# Flash_5 register map
Vendor: Texas Instruments
Peripheral module from a debugger description file (folder msp430).
Registers are 16-bit, read-write, reset 0x0 unless marked. A register's access mark holds for its fields unless they carry their own. Offsets are as the file gives them; lines under a group give offsets from that group; [hi:lo] are bit positions; {n}, {i} and the like mark numbered series; 'fields as' and 'values as' point back to an identical list; <NAME> marks a mode.

## Flash
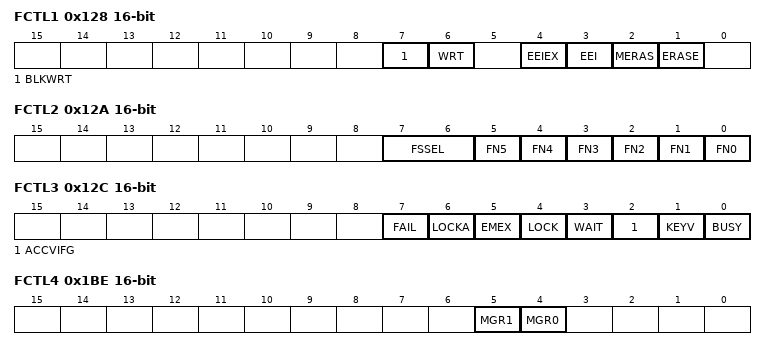
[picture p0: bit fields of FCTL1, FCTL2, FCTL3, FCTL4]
0x128 FCTL1 — FLASH Control 1
  [7] BLKWRT — Enable bit for Flash segment write
  [6] WRT — Enable bit for Flash write
  [4] EEIEX — Enable Emergency Interrupt Exit
  [3] EEI — Enable Erase Interrupts
  [2] MERAS — Enable bit for Flash mass erase
  [1] ERASE — Enable bit for Flash segment erase
0x12A FCTL2 — FLASH Control 2
  [7:6] FSSEL — Flash clock select 0 */ /* to distinguish from USART SSELx
    0=Flash clock select: 0 - ACLK; 1=Flash clock select: 1 - MCLK; 2=Flash clock select: 2 - SMCLK; 3=Flash clock select: 3 - SMCLK
  [n] FN{n} (n=2..5)
  [1] FN1 — 32*FN5 + 16*FN4 + 8*FN3 + 4*FN2 + 2*FN1 + FN0 + 1
  [0] FN0 — Divide Flash clock by 1 to 64 using FN0 to FN5 according to:
0x12C FCTL3 — FLASH Control 3
  [7] FAIL — Last Program or Erase failed
  [6] LOCKA — Segment A Lock bit: read = 1 - Segment is locked (read only)
  [5] EMEX — Flash Emergency Exit
  [4] LOCK — Lock bit: 1 - Flash is locked (read only)
  [3] WAIT — Wait flag for segment write
  [2] ACCVIFG — Flash Access violation flag
  [1] KEYV — Flash Key violation flag
  [0] BUSY — Flash busy: 1
0x1BE FCTL4 — FLASH Control 4
  [5] MGR1 — Marginal read 1 mode.
  [4] MGR0 — Marginal read 0 mode.
